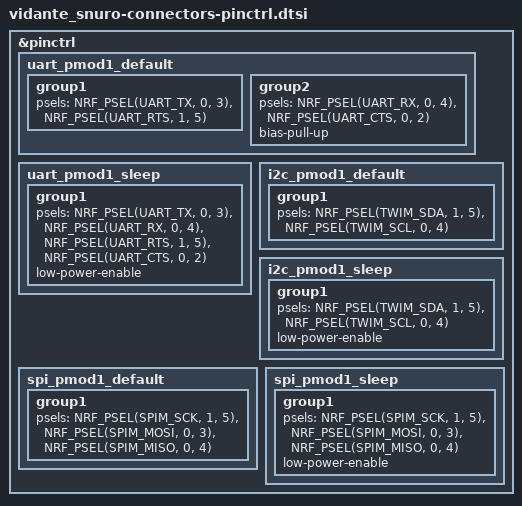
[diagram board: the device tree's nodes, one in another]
/*
 * NOTE: Autogenerated file using gen-connectors-dtsi.py
 *
 * SPDX-License-Identifier: Apache-2.0
 */

&pinctrl {
	uart_pmod1_default: uart_pmod1_default {
		group1 {
			psels = <NRF_PSEL(UART_TX, 0, 3)>,
				<NRF_PSEL(UART_RTS, 1, 5)>;
		};
		group2 {
			psels = <NRF_PSEL(UART_RX, 0, 4)>,
				<NRF_PSEL(UART_CTS, 0, 2)>;
			bias-pull-up;
		};
	};

	uart_pmod1_sleep: uart_pmod1_sleep {
		group1 {
			psels = <NRF_PSEL(UART_TX, 0, 3)>,
				<NRF_PSEL(UART_RX, 0, 4)>,
				<NRF_PSEL(UART_RTS, 1, 5)>,
				<NRF_PSEL(UART_CTS, 0, 2)>;
			low-power-enable;
		};
	};


	i2c_pmod1_default: i2c_pmod1_default {
		group1 {
			psels = <NRF_PSEL(TWIM_SDA, 1, 5)>,
				<NRF_PSEL(TWIM_SCL, 0, 4)>;
		};
	};

	i2c_pmod1_sleep: i2c_pmod1_sleep {
		group1 {
			psels = <NRF_PSEL(TWIM_SDA, 1, 5)>,
				<NRF_PSEL(TWIM_SCL, 0, 4)>;
			low-power-enable;
		};
	};


	spi_pmod1_default: spi_pmod1_default {
		group1 {
			psels = <NRF_PSEL(SPIM_SCK, 1, 5)>,
				<NRF_PSEL(SPIM_MOSI, 0, 3)>,
				<NRF_PSEL(SPIM_MISO, 0, 4)>;
		};
	};

	spi_pmod1_sleep: spi_pmod1_sleep {
		group1 {
			psels = <NRF_PSEL(SPIM_SCK, 1, 5)>,
				<NRF_PSEL(SPIM_MOSI, 0, 3)>,
				<NRF_PSEL(SPIM_MISO, 0, 4)>;
			low-power-enable;
		};
	};

};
